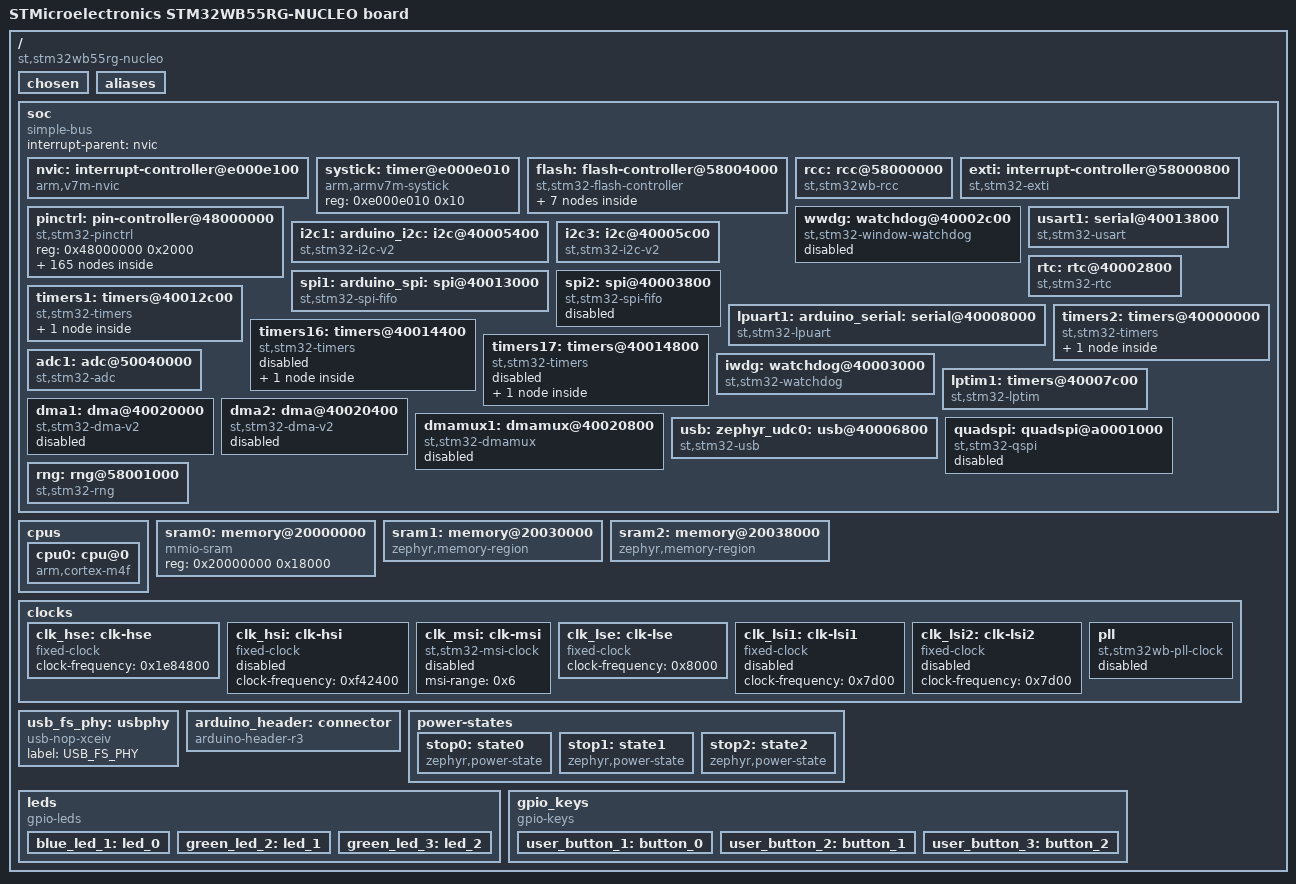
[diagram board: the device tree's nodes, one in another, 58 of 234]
/dts-v1/;

/ {
	#address-cells = < 0x1 >;
	#size-cells = < 0x1 >;
	model = "STMicroelectronics STM32WB55RG-NUCLEO board";
	compatible = "st,stm32wb55rg-nucleo";
	chosen {
		zephyr,entropy = &rng;
		zephyr,flash-controller = &flash;
		zephyr,console = &usart1;
		zephyr,shell-uart = &usart1;
		zephyr,bt-mon-uart = &lpuart1;
		zephyr,sram = &sram0;
		zephyr,flash = &flash0;
		zephyr,code-partition = &slot0_partition;
	};
	aliases {
		led0 = &green_led_2;
		sw0 = &user_button_1;
		sw1 = &user_button_2;
		sw2 = &user_button_3;
	};
	soc {
		#address-cells = < 0x1 >;
		#size-cells = < 0x1 >;
		compatible = "simple-bus";
		interrupt-parent = < &nvic >;
		ranges;
		nvic: interrupt-controller@e000e100 {
			#address-cells = < 0x1 >;
			compatible = "arm,v7m-nvic";
			reg = < 0xe000e100 0xc00 >;
			interrupt-controller;
			#interrupt-cells = < 0x2 >;
			arm,num-irq-priority-bits = < 0x4 >;
			phandle = < 0x1 >;
		};
		systick: timer@e000e010 {
			compatible = "arm,armv7m-systick";
			reg = < 0xe000e010 0x10 >;
		};
		flash: flash-controller@58004000 {
			compatible = "st,stm32-flash-controller", "st,stm32wb-flash-controller";
			label = "FLASH_CTRL";
			reg = < 0x58004000 0x400 >;
			interrupts = < 0x4 0x0 >;
			clocks = < &rcc 0x6 0x2000000 >;
			#address-cells = < 0x1 >;
			#size-cells = < 0x1 >;
			flash0: flash@8000000 {
				compatible = "st,stm32-nv-flash", "soc-nv-flash";
				label = "FLASH_STM32";
				write-block-size = < 0x8 >;
				erase-block-size = < 0x1000 >;
				max-erase-time = < 0x19 >;
				reg = < 0x8000000 0xca000 >;
				partitions {
					compatible = "fixed-partitions";
					#address-cells = < 0x1 >;
					#size-cells = < 0x1 >;
					boot_partition: partition@0 {
						label = "mcuboot";
						reg = < 0x0 0xc000 >;
					};
					slot0_partition: partition@c000 {
						label = "image-0";
						reg = < 0xc000 0x5a000 >;
					};
					slot1_partition: partition@66000 {
						label = "image-1";
						reg = < 0x66000 0x5a000 >;
					};
					scratch_partition: partition@c0000 {
						label = "image-scratch";
						reg = < 0xc0000 0x4000 >;
					};
					storage_partition: partition@c4000 {
						label = "storage";
						reg = < 0xc4000 0x2000 >;
					};
				};
			};
		};
		rcc: rcc@58000000 {
			compatible = "st,stm32wb-rcc";
			#clock-cells = < 0x2 >;
			reg = < 0x58000000 0x400 >;
			clocks = < &clk_hse >;
			clock-frequency = < 0x1e84800 >;
			cpu1-prescaler = < 0x1 >;
			cpu2-prescaler = < 0x1 >;
			ahb4-prescaler = < 0x1 >;
			apb1-prescaler = < 0x1 >;
			apb2-prescaler = < 0x1 >;
			phandle = < 0x2 >;
		};
		exti: interrupt-controller@58000800 {
			compatible = "st,stm32-exti";
			interrupt-controller;
			#interrupt-cells = < 0x1 >;
			reg = < 0x58000800 0x400 >;
		};
		pinctrl: pin-controller@48000000 {
			compatible = "st,stm32-pinctrl";
			#address-cells = < 0x1 >;
			#size-cells = < 0x1 >;
			reg = < 0x48000000 0x2000 >;
			gpioa: gpio@48000000 {
				compatible = "st,stm32-gpio";
				gpio-controller;
				#gpio-cells = < 0x2 >;
				reg = < 0x48000000 0x400 >;
				clocks = < &rcc 0x1 0x1 >;
				label = "GPIOA";
				phandle = < 0x1a >;
			};
			gpiob: gpio@48000400 {
				compatible = "st,stm32-gpio";
				gpio-controller;
				#gpio-cells = < 0x2 >;
				reg = < 0x48000400 0x400 >;
				clocks = < &rcc 0x1 0x2 >;
				label = "GPIOB";
				phandle = < 0x1b >;
			};
			gpioc: gpio@48000800 {
				compatible = "st,stm32-gpio";
				gpio-controller;
				#gpio-cells = < 0x2 >;
				reg = < 0x48000800 0x400 >;
				clocks = < &rcc 0x1 0x4 >;
				label = "GPIOC";
				phandle = < 0x19 >;
			};
			gpiod: gpio@48000c00 {
				compatible = "st,stm32-gpio";
				gpio-controller;
				#gpio-cells = < 0x2 >;
				reg = < 0x48000c00 0x400 >;
				clocks = < &rcc 0x1 0x8 >;
				label = "GPIOD";
				phandle = < 0x1c >;
			};
			gpioe: gpio@48001000 {
				compatible = "st,stm32-gpio";
				gpio-controller;
				#gpio-cells = < 0x2 >;
				reg = < 0x48001000 0x400 >;
				clocks = < &rcc 0x1 0x10 >;
				label = "GPIOE";
			};
			gpioh: gpio@48001c00 {
				compatible = "st,stm32-gpio";
				gpio-controller;
				#gpio-cells = < 0x2 >;
				reg = < 0x48001c00 0x400 >;
				clocks = < &rcc 0x1 0x80 >;
				label = "GPIOH";
			};
			adc1_in5_pa0: adc1_in5_pa0 {
				pinmux = < 0x10 >;
			};
			adc1_in6_pa1: adc1_in6_pa1 {
				pinmux = < 0x30 >;
			};
			adc1_in7_pa2: adc1_in7_pa2 {
				pinmux = < 0x50 >;
			};
			adc1_in8_pa3: adc1_in8_pa3 {
				pinmux = < 0x70 >;
			};
			adc1_in9_pa4: adc1_in9_pa4 {
				pinmux = < 0x90 >;
			};
			adc1_in10_pa5: adc1_in10_pa5 {
				pinmux = < 0xb0 >;
			};
			adc1_in11_pa6: adc1_in11_pa6 {
				pinmux = < 0xd0 >;
			};
			adc1_in12_pa7: adc1_in12_pa7 {
				pinmux = < 0xf0 >;
			};
			adc1_in15_pa8: adc1_in15_pa8 {
				pinmux = < 0x110 >;
			};
			adc1_in16_pa9: adc1_in16_pa9 {
				pinmux = < 0x130 >;
			};
			adc1_in1_pc0: adc1_in1_pc0 {
				pinmux = < 0x410 >;
			};
			adc1_in2_pc1: adc1_in2_pc1 {
				pinmux = < 0x430 >;
			};
			adc1_in3_pc2: adc1_in3_pc2 {
				pinmux = < 0x450 >;
				phandle = < 0x12 >;
			};
			adc1_in4_pc3: adc1_in4_pc3 {
				pinmux = < 0x470 >;
			};
			adc1_in13_pc4: adc1_in13_pc4 {
				pinmux = < 0x490 >;
			};
			adc1_in14_pc5: adc1_in14_pc5 {
				pinmux = < 0x4b0 >;
			};
			analog_pa0: analog_pa0 {
				pinmux = < 0x10 >;
			};
			analog_pa1: analog_pa1 {
				pinmux = < 0x30 >;
			};
			analog_pa2: analog_pa2 {
				pinmux = < 0x50 >;
			};
			analog_pa3: analog_pa3 {
				pinmux = < 0x70 >;
			};
			analog_pa4: analog_pa4 {
				pinmux = < 0x90 >;
			};
			analog_pa5: analog_pa5 {
				pinmux = < 0xb0 >;
			};
			analog_pa6: analog_pa6 {
				pinmux = < 0xd0 >;
			};
			analog_pa7: analog_pa7 {
				pinmux = < 0xf0 >;
			};
			analog_pa8: analog_pa8 {
				pinmux = < 0x110 >;
			};
			analog_pa9: analog_pa9 {
				pinmux = < 0x130 >;
			};
			analog_pa10: analog_pa10 {
				pinmux = < 0x150 >;
			};
			analog_pa11: analog_pa11 {
				pinmux = < 0x170 >;
			};
			analog_pa12: analog_pa12 {
				pinmux = < 0x190 >;
			};
			analog_pa13: analog_pa13 {
				pinmux = < 0x1b0 >;
			};
			analog_pa14: analog_pa14 {
				pinmux = < 0x1d0 >;
			};
			analog_pa15: analog_pa15 {
				pinmux = < 0x1f0 >;
			};
			analog_pb0: analog_pb0 {
				pinmux = < 0x210 >;
			};
			analog_pb1: analog_pb1 {
				pinmux = < 0x230 >;
			};
			analog_pb2: analog_pb2 {
				pinmux = < 0x250 >;
			};
			analog_pb3: analog_pb3 {
				pinmux = < 0x270 >;
			};
			analog_pb4: analog_pb4 {
				pinmux = < 0x290 >;
			};
			analog_pb5: analog_pb5 {
				pinmux = < 0x2b0 >;
			};
			analog_pb6: analog_pb6 {
				pinmux = < 0x2d0 >;
			};
			analog_pb7: analog_pb7 {
				pinmux = < 0x2f0 >;
			};
			analog_pb8: analog_pb8 {
				pinmux = < 0x310 >;
			};
			analog_pb9: analog_pb9 {
				pinmux = < 0x330 >;
			};
			analog_pb10: analog_pb10 {
				pinmux = < 0x350 >;
			};
			analog_pb11: analog_pb11 {
				pinmux = < 0x370 >;
			};
			analog_pb12: analog_pb12 {
				pinmux = < 0x390 >;
			};
			analog_pb13: analog_pb13 {
				pinmux = < 0x3b0 >;
			};
			analog_pb14: analog_pb14 {
				pinmux = < 0x3d0 >;
			};
			analog_pb15: analog_pb15 {
				pinmux = < 0x3f0 >;
			};
			analog_pc0: analog_pc0 {
				pinmux = < 0x410 >;
			};
			analog_pc1: analog_pc1 {
				pinmux = < 0x430 >;
			};
			analog_pc2: analog_pc2 {
				pinmux = < 0x450 >;
			};
			analog_pc3: analog_pc3 {
				pinmux = < 0x470 >;
			};
			analog_pc4: analog_pc4 {
				pinmux = < 0x490 >;
			};
			analog_pc5: analog_pc5 {
				pinmux = < 0x4b0 >;
			};
			analog_pc6: analog_pc6 {
				pinmux = < 0x4d0 >;
			};
			analog_pc10: analog_pc10 {
				pinmux = < 0x550 >;
			};
			analog_pc11: analog_pc11 {
				pinmux = < 0x570 >;
			};
			analog_pc12: analog_pc12 {
				pinmux = < 0x590 >;
			};
			analog_pc13: analog_pc13 {
				pinmux = < 0x5b0 >;
			};
			analog_pc14: analog_pc14 {
				pinmux = < 0x5d0 >;
			};
			analog_pc15: analog_pc15 {
				pinmux = < 0x5f0 >;
			};
			analog_pd0: analog_pd0 {
				pinmux = < 0x610 >;
			};
			analog_pd1: analog_pd1 {
				pinmux = < 0x630 >;
			};
			analog_pe4: analog_pe4 {
				pinmux = < 0x890 >;
			};
			analog_ph3: analog_ph3 {
				pinmux = < 0xe70 >;
			};
			i2c1_scl_pa9: i2c1_scl_pa9 {
				pinmux = < 0x124 >;
				bias-pull-up;
				drive-open-drain;
			};
			i2c1_scl_pb6: i2c1_scl_pb6 {
				pinmux = < 0x2c4 >;
				bias-pull-up;
				drive-open-drain;
			};
			i2c1_scl_pb8: i2c1_scl_pb8 {
				pinmux = < 0x304 >;
				bias-pull-up;
				drive-open-drain;
				phandle = < 0x6 >;
			};
			i2c3_scl_pa7: i2c3_scl_pa7 {
				pinmux = < 0xe4 >;
				bias-pull-up;
				drive-open-drain;
			};
			i2c3_scl_pb10: i2c3_scl_pb10 {
				pinmux = < 0x344 >;
				bias-pull-up;
				drive-open-drain;
			};
			i2c3_scl_pb13: i2c3_scl_pb13 {
				pinmux = < 0x3a4 >;
				bias-pull-up;
				drive-open-drain;
			};
			i2c3_scl_pc0: i2c3_scl_pc0 {
				pinmux = < 0x404 >;
				bias-pull-up;
				drive-open-drain;
				phandle = < 0x8 >;
			};
			i2c1_sda_pa10: i2c1_sda_pa10 {
				pinmux = < 0x144 >;
				bias-pull-up;
				drive-open-drain;
			};
			i2c1_sda_pb7: i2c1_sda_pb7 {
				pinmux = < 0x2e4 >;
				bias-pull-up;
				drive-open-drain;
			};
			i2c1_sda_pb9: i2c1_sda_pb9 {
				pinmux = < 0x324 >;
				bias-pull-up;
				drive-open-drain;
				phandle = < 0x7 >;
			};
			i2c3_sda_pb4: i2c3_sda_pb4 {
				pinmux = < 0x284 >;
				bias-pull-up;
				drive-open-drain;
			};
			i2c3_sda_pb11: i2c3_sda_pb11 {
				pinmux = < 0x364 >;
				bias-pull-up;
				drive-open-drain;
			};
			i2c3_sda_pb14: i2c3_sda_pb14 {
				pinmux = < 0x3c4 >;
				bias-pull-up;
				drive-open-drain;
			};
			i2c3_sda_pc1: i2c3_sda_pc1 {
				pinmux = < 0x424 >;
				bias-pull-up;
				drive-open-drain;
				phandle = < 0x9 >;
			};
			quadspi_bk1_ncs_pa2: quadspi_bk1_ncs_pa2 {
				pinmux = < 0x4a >;
				slew-rate = "very-high-speed";
			};
			quadspi_clk_pa3: quadspi_clk_pa3 {
				pinmux = < 0x6a >;
				slew-rate = "very-high-speed";
			};
			quadspi_bk1_io3_pa6: quadspi_bk1_io3_pa6 {
				pinmux = < 0xca >;
				slew-rate = "very-high-speed";
			};
			quadspi_bk1_io2_pa7: quadspi_bk1_io2_pa7 {
				pinmux = < 0xea >;
				slew-rate = "very-high-speed";
			};
			quadspi_bk1_io1_pb8: quadspi_bk1_io1_pb8 {
				pinmux = < 0x30a >;
				slew-rate = "very-high-speed";
			};
			quadspi_bk1_io0_pb9: quadspi_bk1_io0_pb9 {
				pinmux = < 0x32a >;
				slew-rate = "very-high-speed";
			};
			quadspi_clk_pb10: quadspi_clk_pb10 {
				pinmux = < 0x34a >;
				slew-rate = "very-high-speed";
			};
			quadspi_bk1_ncs_pb11: quadspi_bk1_ncs_pb11 {
				pinmux = < 0x36a >;
				slew-rate = "very-high-speed";
			};
			spi1_miso_pa6: spi1_miso_pa6 {
				pinmux = < 0xc5 >;
				bias-pull-down;
				phandle = < 0xc >;
			};
			spi1_miso_pa11: spi1_miso_pa11 {
				pinmux = < 0x165 >;
				bias-pull-down;
			};
			spi1_miso_pb4: spi1_miso_pb4 {
				pinmux = < 0x285 >;
				bias-pull-down;
			};
			spi2_miso_pb14: spi2_miso_pb14 {
				pinmux = < 0x3c5 >;
				bias-pull-down;
			};
			spi2_miso_pc2: spi2_miso_pc2 {
				pinmux = < 0x445 >;
				bias-pull-down;
			};
			spi1_mosi_pa7: spi1_mosi_pa7 {
				pinmux = < 0xe5 >;
				bias-pull-down;
				phandle = < 0xd >;
			};
			spi1_mosi_pa12: spi1_mosi_pa12 {
				pinmux = < 0x185 >;
				bias-pull-down;
			};
			spi1_mosi_pb5: spi1_mosi_pb5 {
				pinmux = < 0x2a5 >;
				bias-pull-down;
			};
			spi2_mosi_pb15: spi2_mosi_pb15 {
				pinmux = < 0x3e5 >;
				bias-pull-down;
			};
			spi2_mosi_pc1: spi2_mosi_pc1 {
				pinmux = < 0x423 >;
				bias-pull-down;
			};
			spi2_mosi_pc3: spi2_mosi_pc3 {
				pinmux = < 0x465 >;
				bias-pull-down;
			};
			spi1_nss_pa4: spi1_nss_pa4 {
				pinmux = < 0x85 >;
				bias-pull-up;
				phandle = < 0xa >;
			};
			spi1_nss_pa15: spi1_nss_pa15 {
				pinmux = < 0x1e5 >;
				bias-pull-up;
			};
			spi1_nss_pb2: spi1_nss_pb2 {
				pinmux = < 0x245 >;
				bias-pull-up;
			};
			spi2_nss_pb9: spi2_nss_pb9 {
				pinmux = < 0x325 >;
				bias-pull-up;
			};
			spi2_nss_pb12: spi2_nss_pb12 {
				pinmux = < 0x385 >;
				bias-pull-up;
			};
			spi2_nss_pd0: spi2_nss_pd0 {
				pinmux = < 0x605 >;
				bias-pull-up;
			};
			spi1_sck_pa1: spi1_sck_pa1 {
				pinmux = < 0x25 >;
				bias-pull-down;
				slew-rate = "very-high-speed";
			};
			spi1_sck_pa5: spi1_sck_pa5 {
				pinmux = < 0xa5 >;
				bias-pull-down;
				slew-rate = "very-high-speed";
				phandle = < 0xb >;
			};
			spi1_sck_pb3: spi1_sck_pb3 {
				pinmux = < 0x265 >;
				bias-pull-down;
				slew-rate = "very-high-speed";
			};
			spi2_sck_pa9: spi2_sck_pa9 {
				pinmux = < 0x125 >;
				bias-pull-down;
				slew-rate = "very-high-speed";
			};
			spi2_sck_pb10: spi2_sck_pb10 {
				pinmux = < 0x345 >;
				bias-pull-down;
				slew-rate = "very-high-speed";
			};
			spi2_sck_pb13: spi2_sck_pb13 {
				pinmux = < 0x3a5 >;
				bias-pull-down;
				slew-rate = "very-high-speed";
			};
			spi2_sck_pd1: spi2_sck_pd1 {
				pinmux = < 0x625 >;
				bias-pull-down;
				slew-rate = "very-high-speed";
			};
			tim1_ch1n_pa7: tim1_ch1n_pa7 {
				pinmux = < 0xe1 >;
			};
			tim1_ch1_pa8: tim1_ch1_pa8 {
				pinmux = < 0x101 >;
				phandle = < 0x10 >;
			};
			tim1_ch2_pa9: tim1_ch2_pa9 {
				pinmux = < 0x121 >;
			};
			tim1_ch3_pa10: tim1_ch3_pa10 {
				pinmux = < 0x141 >;
			};
			tim1_ch4_pa11: tim1_ch4_pa11 {
				pinmux = < 0x161 >;
			};
			tim1_ch2n_pb8: tim1_ch2n_pb8 {
				pinmux = < 0x301 >;
			};
			tim1_ch3n_pb9: tim1_ch3n_pb9 {
				pinmux = < 0x321 >;
			};
			tim1_ch1n_pb13: tim1_ch1n_pb13 {
				pinmux = < 0x3a1 >;
			};
			tim1_ch2n_pb14: tim1_ch2n_pb14 {
				pinmux = < 0x3c1 >;
			};
			tim1_ch3n_pb15: tim1_ch3n_pb15 {
				pinmux = < 0x3e1 >;
			};
			tim2_ch1_pa0: tim2_ch1_pa0 {
				pinmux = < 0x1 >;
			};
			tim2_ch2_pa1: tim2_ch2_pa1 {
				pinmux = < 0x21 >;
			};
			tim2_ch3_pa2: tim2_ch3_pa2 {
				pinmux = < 0x41 >;
			};
			tim2_ch4_pa3: tim2_ch4_pa3 {
				pinmux = < 0x61 >;
			};
			tim2_ch1_pa5: tim2_ch1_pa5 {
				pinmux = < 0xa1 >;
			};
			tim2_ch1_pa15: tim2_ch1_pa15 {
				pinmux = < 0x1e1 >;
				phandle = < 0x11 >;
			};
			tim2_ch2_pb3: tim2_ch2_pb3 {
				pinmux = < 0x261 >;
			};
			tim2_ch3_pb10: tim2_ch3_pb10 {
				pinmux = < 0x341 >;
			};
			tim2_ch4_pb11: tim2_ch4_pb11 {
				pinmux = < 0x361 >;
			};
			tim16_ch1_pa6: tim16_ch1_pa6 {
				pinmux = < 0xce >;
			};
			tim16_ch1n_pb6: tim16_ch1n_pb6 {
				pinmux = < 0x2ce >;
			};
			tim16_ch1_pb8: tim16_ch1_pb8 {
				pinmux = < 0x30e >;
			};
			tim17_ch1_pa7: tim17_ch1_pa7 {
				pinmux = < 0xee >;
			};
			tim17_ch1n_pb7: tim17_ch1n_pb7 {
				pinmux = < 0x2ee >;
			};
			tim17_ch1_pb9: tim17_ch1_pb9 {
				pinmux = < 0x32e >;
			};
			lpuart1_cts_pa6: lpuart1_cts_pa6 {
				pinmux = < 0xc8 >;
				bias-pull-up;
				drive-open-drain;
			};
			usart1_cts_pa11: usart1_cts_pa11 {
				pinmux = < 0x167 >;
				bias-pull-up;
				drive-open-drain;
			};
			usart1_cts_pb4: usart1_cts_pb4 {
				pinmux = < 0x287 >;
				bias-pull-up;
				drive-open-drain;
			};
			lpuart1_cts_pb13: lpuart1_cts_pb13 {
				pinmux = < 0x3a8 >;
				bias-pull-up;
				drive-open-drain;
			};
			usart1_rts_pa12: usart1_rts_pa12 {
				pinmux = < 0x187 >;
				bias-pull-up;
				drive-open-drain;
			};
			lpuart1_rts_pb1: lpuart1_rts_pb1 {
				pinmux = < 0x228 >;
				bias-pull-up;
				drive-open-drain;
			};
			usart1_rts_pb3: usart1_rts_pb3 {
				pinmux = < 0x267 >;
				bias-pull-up;
				drive-open-drain;
			};
			lpuart1_rts_pb12: lpuart1_rts_pb12 {
				pinmux = < 0x388 >;
				bias-pull-up;
				drive-open-drain;
			};
			lpuart1_rx_pa3: lpuart1_rx_pa3 {
				pinmux = < 0x68 >;
				phandle = < 0xf >;
			};
			usart1_rx_pa10: usart1_rx_pa10 {
				pinmux = < 0x147 >;
			};
			lpuart1_rx_pa12: lpuart1_rx_pa12 {
				pinmux = < 0x188 >;
			};
			usart1_rx_pb7: usart1_rx_pb7 {
				pinmux = < 0x2e7 >;
				phandle = < 0x5 >;
			};
			lpuart1_rx_pb10: lpuart1_rx_pb10 {
				pinmux = < 0x348 >;
			};
			lpuart1_rx_pc0: lpuart1_rx_pc0 {
				pinmux = < 0x408 >;
			};
			lpuart1_tx_pa2: lpuart1_tx_pa2 {
				pinmux = < 0x48 >;
				bias-pull-up;
				phandle = < 0xe >;
			};
			usart1_tx_pa9: usart1_tx_pa9 {
				pinmux = < 0x127 >;
				bias-pull-up;
			};
			lpuart1_tx_pb5: lpuart1_tx_pb5 {
				pinmux = < 0x2a8 >;
				bias-pull-up;
			};
			usart1_tx_pb6: usart1_tx_pb6 {
				pinmux = < 0x2c7 >;
				bias-pull-up;
				phandle = < 0x4 >;
			};
			lpuart1_tx_pb11: lpuart1_tx_pb11 {
				pinmux = < 0x368 >;
				bias-pull-up;
			};
			lpuart1_tx_pc1: lpuart1_tx_pc1 {
				pinmux = < 0x428 >;
				bias-pull-up;
			};
			usb_dm_pa11: usb_dm_pa11 {
				pinmux = < 0x16a >;
				phandle = < 0x14 >;
			};
			usb_dp_pa12: usb_dp_pa12 {
				pinmux = < 0x18a >;
				phandle = < 0x15 >;
			};
			usb_noe_pa13: usb_noe_pa13 {
				pinmux = < 0x1aa >;
			};
		};
		wwdg: watchdog@40002c00 {
			compatible = "st,stm32-window-watchdog";
			reg = < 0x40002c00 0x400 >;
			clocks = < &rcc 0x2 0x800 >;
			label = "WWDG";
			interrupts = < 0x0 0x7 >;
			status = "disabled";
		};
		usart1: serial@40013800 {
			compatible = "st,stm32-usart", "st,stm32-uart";
			reg = < 0x40013800 0x400 >;
			clocks = < &rcc 0x3 0x4000 >;
			interrupts = < 0x24 0x0 >;
			status = "okay";
			label = "UART_1";
			pinctrl-0 = < &usart1_tx_pb6 &usart1_rx_pb7 >;
			pinctrl-names = "default";
			current-speed = < 0x1c200 >;
		};
		i2c1: arduino_i2c: i2c@40005400 {
			compatible = "st,stm32-i2c-v2";
			clock-frequency = < 0x61a80 >;
			#address-cells = < 0x1 >;
			#size-cells = < 0x0 >;
			reg = < 0x40005400 0x400 >;
			clocks = < &rcc 0x2 0x200000 >;
			interrupts = < 0x1e 0x0 >, < 0x1f 0x0 >;
			interrupt-names = "event", "error";
			status = "okay";
			label = "I2C_1";
			pinctrl-0 = < &i2c1_scl_pb8 &i2c1_sda_pb9 >;
			pinctrl-names = "default";
		};
		i2c3: i2c@40005c00 {
			compatible = "st,stm32-i2c-v2";
			clock-frequency = < 0x61a80 >;
			#address-cells = < 0x1 >;
			#size-cells = < 0x0 >;
			reg = < 0x40005c00 0x400 >;
			clocks = < &rcc 0x2 0x800000 >;
			interrupts = < 0x20 0x0 >, < 0x21 0x0 >;
			interrupt-names = "event", "error";
			status = "okay";
			label = "I2C_3";
			pinctrl-0 = < &i2c3_scl_pc0 &i2c3_sda_pc1 >;
			pinctrl-names = "default";
		};
		rtc: rtc@40002800 {
			compatible = "st,stm32-rtc";
			reg = < 0x40002800 0x400 >;
			interrupts = < 0x29 0x0 >;
			clocks = < &rcc 0x2 0x400 >;
			prescaler = < 0x8000 >;
			status = "okay";
			label = "RTC_0";
		};
		spi1: arduino_spi: spi@40013000 {
			compatible = "st,stm32-spi-fifo", "st,stm32-spi";
			#address-cells = < 0x1 >;
			#size-cells = < 0x0 >;
			reg = < 0x40013000 0x400 >;
			interrupts = < 0x22 0x5 >;
			clocks = < &rcc 0x3 0x1000 >;
			status = "okay";
			label = "SPI_1";
			pinctrl-0 = < &spi1_nss_pa4 &spi1_sck_pa5 &spi1_miso_pa6 &spi1_mosi_pa7 >;
			pinctrl-names = "default";
		};
		spi2: spi@40003800 {
			compatible = "st,stm32-spi-fifo", "st,stm32-spi";
			#address-cells = < 0x1 >;
			#size-cells = < 0x0 >;
			reg = < 0x40003800 0x400 >;
			interrupts = < 0x23 0x5 >;
			clocks = < &rcc 0x2 0x4000 >;
			status = "disabled";
			label = "SPI_2";
		};
		lpuart1: arduino_serial: serial@40008000 {
			compatible = "st,stm32-lpuart", "st,stm32-uart";
			reg = < 0x40008000 0x400 >;
			clocks = < &rcc 0x4 0x1 >;
			interrupts = < 0x25 0x0 >;
			status = "okay";
			label = "LPUART_1";
			pinctrl-0 = < &lpuart1_tx_pa2 &lpuart1_rx_pa3 >;
			pinctrl-names = "default";
			current-speed = < 0x1c200 >;
		};
		timers1: timers@40012c00 {
			compatible = "st,stm32-timers";
			reg = < 0x40012c00 0x400 >;
			clocks = < &rcc 0x3 0x800 >;
			interrupts = < 0x18 0x0 >, < 0x19 0x0 >, < 0x1a 0x0 >, < 0x1b 0x0 >;
			interrupt-names = "brk", "up", "trgcom", "cc";
			st,prescaler = < 0x2710 >;
			status = "okay";
			label = "TIMERS_1";
			pwm1: pwm {
				compatible = "st,stm32-pwm";
				status = "okay";
				label = "PWM_1";
				#pwm-cells = < 0x3 >;
				pinctrl-0 = < &tim1_ch1_pa8 >;
				pinctrl-names = "default";
			};
		};
		timers2: timers@40000000 {
			compatible = "st,stm32-timers";
			reg = < 0x40000000 0x400 >;
			clocks = < &rcc 0x2 0x1 >;
			interrupts = < 0x1c 0x0 >;
			interrupt-names = "global";
			st,prescaler = < 0x0 >;
			status = "okay";
			label = "TIMERS_2";
			pwm2: pwm {
				compatible = "st,stm32-pwm";
				status = "okay";
				label = "PWM_2";
				#pwm-cells = < 0x3 >;
				pinctrl-0 = < &tim2_ch1_pa15 >;
				pinctrl-names = "default";
			};
		};
		timers16: timers@40014400 {
			compatible = "st,stm32-timers";
			reg = < 0x40014400 0x400 >;
			clocks = < &rcc 0x3 0x20000 >;
			interrupts = < 0x19 0x0 >;
			interrupt-names = "global";
			st,prescaler = < 0x0 >;
			status = "disabled";
			label = "TIMERS_16";
			pwm {
				compatible = "st,stm32-pwm";
				status = "disabled";
				label = "PWM_16";
				#pwm-cells = < 0x3 >;
			};
		};
		timers17: timers@40014800 {
			compatible = "st,stm32-timers";
			reg = < 0x40014800 0x400 >;
			clocks = < &rcc 0x3 0x40000 >;
			interrupts = < 0x1a 0x0 >;
			interrupt-names = "global";
			st,prescaler = < 0x0 >;
			status = "disabled";
			label = "TIMERS_17";
			pwm {
				compatible = "st,stm32-pwm";
				status = "disabled";
				label = "PWM_17";
				#pwm-cells = < 0x3 >;
			};
		};
		adc1: adc@50040000 {
			compatible = "st,stm32-adc";
			reg = < 0x50040000 0x400 >;
			clocks = < &rcc 0x1 0x2000 >;
			interrupts = < 0x12 0x0 >;
			status = "okay";
			label = "ADC_1";
			#io-channel-cells = < 0x1 >;
			has-temp-channel;
			has-vref-channel;
			pinctrl-0 = < &adc1_in3_pc2 >;
			pinctrl-names = "default";
		};
		iwdg: watchdog@40003000 {
			compatible = "st,stm32-watchdog";
			reg = < 0x40003000 0x400 >;
			label = "IWDG";
			status = "okay";
		};
		lptim1: timers@40007c00 {
			compatible = "st,stm32-lptim";
			clocks = < &rcc 0x2 0x80000000 >;
			#address-cells = < 0x1 >;
			#size-cells = < 0x0 >;
			reg = < 0x40007c00 0x400 >;
			interrupts = < 0x2f 0x1 >;
			interrupt-names = "wakeup";
			status = "okay";
			label = "LPTIM_1";
		};
		dma1: dma@40020000 {
			compatible = "st,stm32-dma-v2";
			#dma-cells = < 0x3 >;
			reg = < 0x40020000 0x400 >;
			interrupts = < 0xb 0x0 0xc 0x0 0xd 0x0 0xe 0x0 0xf 0x0 0x10 0x0 0x11 0x0 >;
			clocks = < &rcc 0x0 0x1 >;
			dma-requests = < 0x7 >;
			dma-offset = < 0x0 >;
			status = "disabled";
			label = "DMA_1";
		};
		dma2: dma@40020400 {
			compatible = "st,stm32-dma-v2";
			#dma-cells = < 0x3 >;
			reg = < 0x40020400 0x400 >;
			interrupts = < 0x37 0x0 0x38 0x0 0x39 0x0 0x3a 0x0 0x3b 0x0 0x3c 0x0 0x3d 0x0 >;
			clocks = < &rcc 0x0 0x2 >;
			dma-requests = < 0x7 >;
			dma-offset = < 0x7 >;
			status = "disabled";
			label = "DMA_2";
		};
		dmamux1: dmamux@40020800 {
			compatible = "st,stm32-dmamux";
			#dma-cells = < 0x3 >;
			reg = < 0x40020800 0x400 >;
			interrupts = < 0x3e 0x0 >;
			clocks = < &rcc 0x0 0x4 >;
			dma-channels = < 0xe >;
			dma-generators = < 0x4 >;
			dma-requests = < 0x24 >;
			status = "disabled";
			label = "DMAMUX_1";
		};
		usb: zephyr_udc0: usb@40006800 {
			compatible = "st,stm32-usb";
			reg = < 0x40006800 0x400 >;
			interrupts = < 0x14 0x0 >, < 0x13 0x0 >;
			interrupt-names = "usb", "usbhp";
			num-bidir-endpoints = < 0x8 >;
			ram-size = < 0x400 >;
			phys = < &usb_fs_phy >;
			clocks = < &rcc 0x2 0x4000000 >;
			status = "okay";
			label = "USB";
			pinctrl-0 = < &usb_dm_pa11 &usb_dp_pa12 >;
			pinctrl-names = "default";
		};
		quadspi: quadspi@a0001000 {
			compatible = "st,stm32-qspi";
			#address-cells = < 0x1 >;
			#size-cells = < 0x0 >;
			reg = < 0xa0001000 0x400 >;
			interrupts = < 0x32 0x0 >;
			clocks = < &rcc 0x6 0x100 >;
			status = "disabled";
			label = "QUADSPI";
		};
		rng: rng@58001000 {
			compatible = "st,stm32-rng";
			reg = < 0x58001000 0x400 >;
			interrupts = < 0x35 0x0 >;
			clocks = < &rcc 0x6 0x40000 >;
			status = "okay";
			label = "RNG";
		};
	};
	cpus {
		#address-cells = < 0x1 >;
		#size-cells = < 0x0 >;
		cpu0: cpu@0 {
			device_type = "cpu";
			compatible = "arm,cortex-m4f";
			reg = < 0x0 >;
			cpu-power-states = < &stop0 &stop1 &stop2 >;
		};
	};
	sram0: memory@20000000 {
		compatible = "mmio-sram";
		reg = < 0x20000000 0x18000 >;
	};
	sram1: memory@20030000 {
		compatible = "zephyr,memory-region", "mmio-sram";
		reg = < 0x20030000 0x2800 >;
		zephyr,memory-region = "SRAM1";
	};
	sram2: memory@20038000 {
		compatible = "zephyr,memory-region", "mmio-sram";
		reg = < 0x20038000 0x5000 >;
		zephyr,memory-region = "SRAM2";
	};
	clocks {
		clk_hse: clk-hse {
			#clock-cells = < 0x0 >;
			compatible = "fixed-clock";
			clock-frequency = < 0x1e84800 >;
			status = "okay";
			phandle = < 0x3 >;
		};
		clk_hsi: clk-hsi {
			#clock-cells = < 0x0 >;
			compatible = "fixed-clock";
			clock-frequency = < 0xf42400 >;
			status = "disabled";
		};
		clk_msi: clk-msi {
			#clock-cells = < 0x0 >;
			compatible = "st,stm32-msi-clock";
			msi-range = < 0x6 >;
			status = "disabled";
		};
		clk_lse: clk-lse {
			#clock-cells = < 0x0 >;
			compatible = "fixed-clock";
			clock-frequency = < 0x8000 >;
			status = "okay";
		};
		clk_lsi1: clk-lsi1 {
			#clock-cells = < 0x0 >;
			compatible = "fixed-clock";
			clock-frequency = < 0x7d00 >;
			status = "disabled";
		};
		clk_lsi2: clk-lsi2 {
			#clock-cells = < 0x0 >;
			compatible = "fixed-clock";
			clock-frequency = < 0x7d00 >;
			status = "disabled";
		};
		pll: pll {
			#clock-cells = < 0x0 >;
			compatible = "st,stm32wb-pll-clock";
			status = "disabled";
		};
	};
	usb_fs_phy: usbphy {
		compatible = "usb-nop-xceiv";
		#phy-cells = < 0x0 >;
		label = "USB_FS_PHY";
		phandle = < 0x13 >;
	};
	arduino_header: connector {
		compatible = "arduino-header-r3";
		#gpio-cells = < 0x2 >;
		gpio-map-mask = < 0xffffffff 0xffffffc0 >;
		gpio-map-pass-thru = < 0x0 0x3f >;
		gpio-map = < 0x0 0x0 &gpioc 0x0 0x0 >, < 0x1 0x0 &gpioc 0x1 0x0 >, < 0x2 0x0 &gpioa 0x1 0x0 >, < 0x3 0x0 &gpioa 0x0 0x0 >, < 0x4 0x0 &gpioc 0x3 0x0 >, < 0x5 0x0 &gpioc 0x2 0x0 >, < 0x6 0x0 &gpioa 0x3 0x0 >, < 0x7 0x0 &gpioa 0x2 0x0 >, < 0x8 0x0 &gpioc 0x6 0x0 >, < 0x9 0x0 &gpioa 0xa 0x0 >, < 0xa 0x0 &gpioc 0xa 0x0 >, < 0xb 0x0 &gpioa 0xf 0x0 >, < 0xc 0x0 &gpioa 0x8 0x0 >, < 0xd 0x0 &gpioc 0xd 0x0 >, < 0xe 0x0 &gpioc 0xc 0x0 >, < 0xf 0x0 &gpioa 0x9 0x0 >, < 0x10 0x0 &gpioa 0x4 0x0 >, < 0x11 0x0 &gpioa 0x7 0x0 >, < 0x12 0x0 &gpioa 0x6 0x0 >, < 0x13 0x0 &gpioa 0x5 0x0 >, < 0x14 0x0 &gpiob 0x9 0x0 >, < 0x15 0x0 &gpiob 0x8 0x0 >;
	};
	power-states {
		stop0: state0 {
			compatible = "zephyr,power-state";
			power-state-name = "suspend-to-idle";
			substate-id = < 0x1 >;
			min-residency-us = < 0x64 >;
			phandle = < 0x16 >;
		};
		stop1: state1 {
			compatible = "zephyr,power-state";
			power-state-name = "suspend-to-idle";
			substate-id = < 0x2 >;
			min-residency-us = < 0x1f4 >;
			phandle = < 0x17 >;
		};
		stop2: state2 {
			compatible = "zephyr,power-state";
			power-state-name = "suspend-to-idle";
			substate-id = < 0x3 >;
			min-residency-us = < 0x384 >;
			phandle = < 0x18 >;
		};
	};
	leds {
		compatible = "gpio-leds";
		blue_led_1: led_0 {
			gpios = < &gpiob 0x5 0x0 >;
			label = "User LED1";
		};
		green_led_2: led_1 {
			gpios = < &gpiob 0x0 0x0 >;
			label = "User LED2";
		};
		green_led_3: led_2 {
			gpios = < &gpiob 0x1 0x0 >;
			label = "User LED3";
		};
	};
	gpio_keys {
		compatible = "gpio-keys";
		user_button_1: button_0 {
			label = "SW1";
			gpios = < &gpioc 0x4 0x11 >;
		};
		user_button_2: button_1 {
			label = "SW2";
			gpios = < &gpiod 0x0 0x11 >;
		};
		user_button_3: button_2 {
			label = "SW3";
			gpios = < &gpiod 0x1 0x11 >;
		};
	};
};
